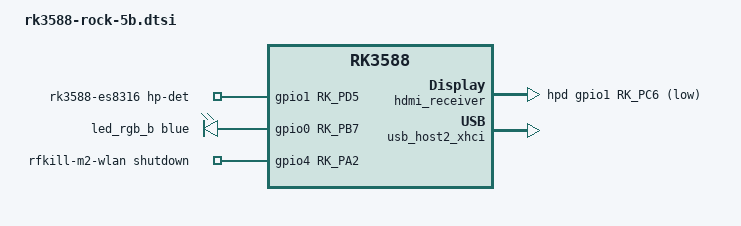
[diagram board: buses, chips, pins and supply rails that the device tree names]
// SPDX-License-Identifier: (GPL-2.0+ OR MIT)

/dts-v1/;

#include "rk3588-rock-5b-5bp-5t.dtsi"

/ {
	analog-sound {
		compatible = "audio-graph-card";
		label = "rk3588-es8316";

		widgets = "Microphone", "Mic Jack",
			  "Headphone", "Headphones";

		routing = "MIC2", "Mic Jack",
			  "Headphones", "HPOL",
			  "Headphones", "HPOR";

		dais = <&i2s0_8ch_p0>;
		hp-det-gpios = <&gpio1 RK_PD5 GPIO_ACTIVE_HIGH>;
		pinctrl-names = "default";
		pinctrl-0 = <&hp_detect>;
	};

	leds {
		compatible = "gpio-leds";
		pinctrl-names = "default";
		pinctrl-0 = <&led_rgb_b>;

		led_rgb_b {
			function = LED_FUNCTION_STATUS;
			color = <LED_COLOR_ID_BLUE>;
			gpios = <&gpio0 RK_PB7 GPIO_ACTIVE_HIGH>;
			linux,default-trigger = "heartbeat";
		};
	};

	rfkill {
		compatible = "rfkill-gpio";
		label = "rfkill-m2-wlan";
		radio-type = "wlan";
		shutdown-gpios = <&gpio4 RK_PA2 GPIO_ACTIVE_HIGH>;
	};
};

&hdmi_receiver {
	hpd-gpios = <&gpio1 RK_PC6 GPIO_ACTIVE_LOW>;
	status = "okay";
};

&pinctrl {
	hdmirx {
		hdmirx_hpd: hdmirx-5v-detection {
			rockchip,pins = <1 RK_PC6 RK_FUNC_GPIO &pcfg_pull_none>;
		};
	};

	leds {
		led_rgb_b: led-rgb-b {
			rockchip,pins = <0 RK_PB7 RK_FUNC_GPIO &pcfg_pull_none>;
		};
	};

	pcie2 {
		pcie2_0_vcc3v3_en: pcie2-0-vcc-en {
			rockchip,pins = <1 RK_PD2 RK_FUNC_GPIO &pcfg_pull_none>;
		};
	};

	sound {
		hp_detect: hp-detect {
			rockchip,pins = <1 RK_PD5 RK_FUNC_GPIO &pcfg_pull_none>;
		};
	};
};

&usb_host2_xhci {
	status = "okay";
};

&vcc3v3_pcie2x1l0 {
	gpios = <&gpio1 RK_PD2 GPIO_ACTIVE_HIGH>;
	pinctrl-names = "default";
	pinctrl-0 = <&pcie2_0_vcc3v3_en>;
	status = "okay";
};
